# T113-S3 register map
Vendor: Allwinner; Series: T113-S3; File version: 0.1
CPU: other 0, little endian, MPU, no FPU, 0 interrupt priority bits
Registers are 32-bit, read-write, reset 0x0 unless marked. A register's access mark holds for its fields unless they carry their own. Offsets are from the block's base; [hi:lo] are bit positions; lines under a group give offsets from that group; {n}, {i} and the like mark numbered series.

## TCON_LCD0
Base 0x05461000
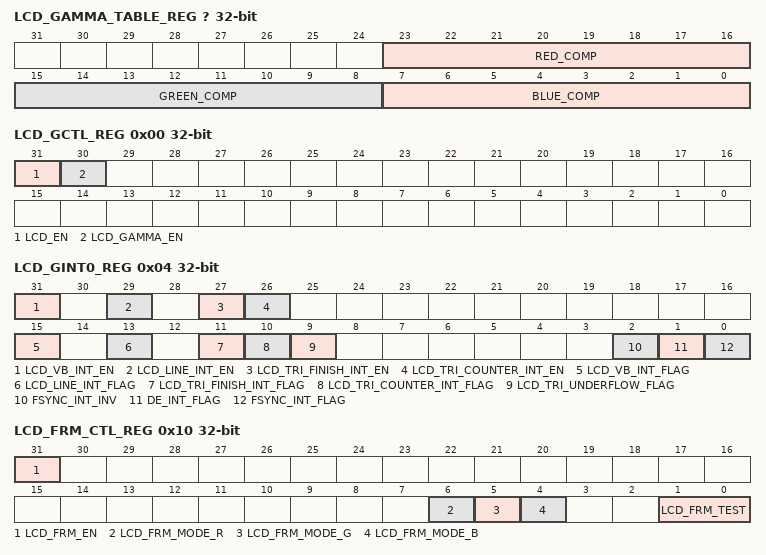
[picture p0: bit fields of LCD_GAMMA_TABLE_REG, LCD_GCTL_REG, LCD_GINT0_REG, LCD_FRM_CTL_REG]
? LCD_GAMMA_TABLE_REG — LCD Gamma Table Register
  [23:16] RED_COMP — Red Component
  [15:8] GREEN_COMP — Green Component
  [7:0] BLUE_COMP — Blue Component
0x00 LCD_GCTL_REG — LCD Global Control Register
  [31] LCD_EN — When it is disabled, the module will be reset to idle state. 0: Disable 1: Enable
    0=Disable; 1=Enable
  [30] LCD_GAMMA_EN — Enable the Gamma correction function. 0: Disable 1: Enable
    0=Disable; 1=Enable
0x04 LCD_GINT0_REG — LCD Global Interrupt Register0
  [31] LCD_VB_INT_EN — Enable the Vb interrupt 0: Disable 1: Enable
    0=Disable; 1=Enable
  [29] LCD_LINE_INT_EN — Enable the line interrupt 0: Disable 1: Enable
    0=Disable; 1=Enable
  [27] LCD_TRI_FINISH_INT_EN — Enable the trigger finish interrupt 0: Disable 1: Enable
    0=Disable; 1=Enable
  [26] LCD_TRI_COUNTER_INT_EN — Enable the trigger counter interrupt 0: Disable 1: Enable
    0=Disable; 1=Enable
  [15] LCD_VB_INT_FLAG write-0-clears — Asserted during vertical no-display period every frame Write 0 to clear it.
  [13] LCD_LINE_INT_FLAG write-0-clears — Trigger when SY0 match the current LCD scan line Write 0 to clear it.
  [11] LCD_TRI_FINISH_INT_FLAG write-0-clears — Trigger when cpu trigger mode finished Write 0 to clear it.
  [10] LCD_TRI_COUNTER_INT_FLAG write-0-clears — Trigger when tri counter reaches this value Write 0 to clear it.
  [9] LCD_TRI_UNDERFLOW_FLAG write-0-clears — Only used in dsi video mode, tri when sync by dsi but not finish Write 0 to clear it.
  [2] FSYNC_INT_INV write-0-clears — Enable the fsync interrupt to set signal inverse polarity. When FSYNC is positive, this bit must be 1. And vice versa.
  [1] DE_INT_FLAG write-0-clears — Asserted at the first valid line in every frame Write 0 to clear it.
  [0] FSYNC_INT_FLAG write-0-clears — Asserted at the fsync signal in every frame Write 0 to clear it.
0x08 LCD_GINT1_REG — LCD Global Interrupt Register1
  [27:16] LCD_LINE_INT_NUM — Scan line for LCD line trigger (including inactive lines). Setting it for the specified line for trigger0.
0x10 LCD_FRM_CTL_REG — LCD FRM Control Register
  [31] LCD_FRM_EN — Enable the dither function 0: Disable 1: Enable
    0=Disable; 1=Enable
  [6] LCD_FRM_MODE_R — The R component output bits in dither function 0: 6-bit frm output 1: 5-bit frm output
    0=6-bit frm output; 1=5-bit frm output
  [5] LCD_FRM_MODE_G — The G component output bits in dither function 0: 6-bit frm output 1: 5-bit frm output
    0=6-bit frm output; 1=5-bit frm output
  [4] LCD_FRM_MODE_B — The B component output bits in dither function 0: 6-bit frm output 1: 5-bit frm output
    0=6-bit frm output; 1=5-bit frm output
  [1:0] LCD_FRM_TEST — Set the test mode of dither function 00: FRM 01: Half 5-/6-bit, half FRM 10: Half 8-bit, half FRM 11: Half 8-bit, half 5-/6-bit
{0x14+4i} xNx[{i}] (i=0..5) — xNx[{i}]
  [24:0] SEED_VALUE — Set the seed used in dither function N=0: Pixel_Seed_R N=1: Pixel_Seed_G N=2: Pixel_Seed_B N=3: Line_Seed_R N=4: Line_Seed_G N=5: Line_Seed_B
{0x2C+4i} LCD_FRM_TAB_REG[{i}] (i=0..3) — LCD FRM Table Register (N=0,1,2,3)
  [31:0] FRM_TABLE_VALUE — Set the data used in dither function Usually set as follows: Table0 = 0x01010000 Table1 = 0x15151111 Table2 = 0x57575555 Table3 = 0x7f7f7777
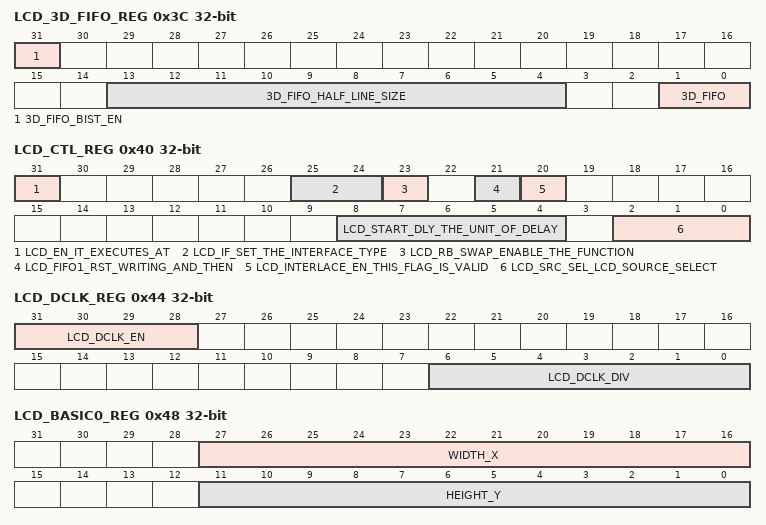
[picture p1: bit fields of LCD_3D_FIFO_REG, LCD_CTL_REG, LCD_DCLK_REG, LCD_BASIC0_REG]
0x3C LCD_3D_FIFO_REG — LCD 3D FIFO Register
  [31] 3D_FIFO_BIST_EN — Enable the 3D fifo bist test function 0: Disable 1: Enable
    0=Disable; 1=Enable
  [13:4] 3D_FIFO_HALF_LINE_SIZE — The number of data in half line=3D_FIFO_HALF_LINE_SIZE+1, only valid when 3D_FIFO_SETTING is set as 2.
  [1:0] 3D_FIFO — Set the work mode of 3D FIFO 00: Bypass 01: Used as normal FIFO 10: Used as 3D interlace FIFO 11: Reserved
0x40 LCD_CTL_REG — LCD Control Register
  [31] LCD_EN_IT_EXECUTES_AT — LCD_EN It executes at the beginning of the first blank line of LCD timing. 0: Disable 1: Enable
    0=Disable; 1=Enable
  [25:24] LCD_IF_SET_THE_INTERFACE_TYPE — LCD_IF Set the interface type of LCD controller. 00: HV(Sync+DE) 01: 8080 I/F 1x: Reserved
    0=HV_openingparen_Sync_plus_DE_closingparen_ (HV(Sync+DE)); 1=8080 I/F
  [23] LCD_RB_SWAP_ENABLE_THE_FUNCTION — LCD_RB_SWAP Enable the function to swap red data and blue data in fifo1. 0: Default 1: Swap RED and BLUE data at FIFO1
    0=Default; 1=Swap RED and BLUE data at FIFO1
  [21] LCD_FIFO1_RST_WRITING_AND_THEN — LCD_FIFO1_RST Writing 1 and then 0 to this bit will reset FIFO 1 Note: 1 holding time must more than 1 DCLK
  [20] LCD_INTERLACE_EN_THIS_FLAG_IS_VALID — LCD_INTERLACE_EN This flag is valid only when LCD_EN == 1 0: Disable 1: Enable
    0=Disable; 1=Enable
  [8:4] LCD_START_DLY_THE_UNIT_OF_DELAY — LCD_START_DLY The unit of delay is T . Note: Valid only when LCD_EN == 1
  [2:0] LCD_SRC_SEL_LCD_SOURCE_SELECT — LCD_SRC_SEL LCD Source Select 000: DE 001: Color Check 010: Grayscale Check 011: Black by White Check 100: Test Data all 0 101: Test Data all 1 110: Reversed 111: Gridding Check
0x44 LCD_DCLK_REG — LCD Data Clock Register
  [31:28] LCD_DCLK_EN — LCD clock enable 0000: dclk_en = 0; dclk1_en = 0; dclk2_en = 0; dclkm2_en = 0; 0001: dclk_en = 1; dclk1_en = 0; dclk2_en = 0; dclkm2_en = 0; 0010: dclk_en = 1; dclk1_en = 0; dclk2_en = 0; dclkm2_en = 1; 0011: dclk_en = 1; dclk1_en = 1; dclk2_en = 0; dclkm2_en = 0; 0101: dclk_en = 1; dclk1_en = 0; dclk2_en = 1; dclkm2_en = 0; 1111: dclk_en = 1; dclk1_en = 1; dclk2_en = 1; dclkm2_en = 1; Others:Reversed
  [6:0] LCD_DCLK_DIV — Tdclk = Tsclk/DCLKDIV Note: 1.If dclk1&dclk2 are used, DCLKDIV >=6 2.If only dclk is used, DCLKDIV >=1
0x48 LCD_BASIC0_REG — LCD Basic Timing Register0
  [27:16] WIDTH_X — Panel width is X+1
  [11:0] HEIGHT_Y — Panel height is Y+1
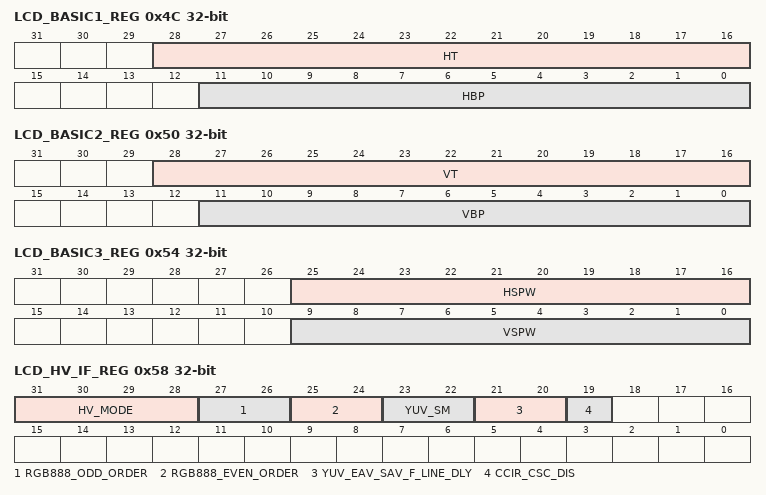
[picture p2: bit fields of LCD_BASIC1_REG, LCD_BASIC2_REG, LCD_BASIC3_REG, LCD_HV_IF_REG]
0x4C LCD_BASIC1_REG — LCD Basic Timing Register1
  [28:16] HT — Thcycle = (HT+1) * Tdclk Computation: 1) parallel: HT = X + BLANK Limitation: 1) parallel: HT >= (HBP +1) + (X+1) +2 2) serial 1: HT >= (HBP +1) + (X+1) *3+2 3) serial 2: HT >= (HBP +1) + (X+1) *3/2+2
  [11:0] HBP — Horizontal back porch (in dclk) Thbp = (HBP +1) * Tdclk
0x50 LCD_BASIC2_REG — LCD Basic Timing Register2
  [28:16] VT — TVT = (VT)/2 * Thsync VT/2 >= (VBP+1 ) + (Y+1) +2
  [11:0] VBP — Tvbp = (VBP +1) * Thsync
0x54 LCD_BASIC3_REG — LCD Basic Timing Register3
  [25:16] HSPW — Thspw = (HSPW+1) * Tdclk HT > (HSPW+1)
  [9:0] VSPW — Tvspw = (VSPW+1) * Thsync VT/2 > (VSPW+1)
0x58 LCD_HV_IF_REG — LCD HV Panel Interface Register
  [31:28] HV_MODE — Set the HV mode of LCD controller 0000: 24-bit/1-cycle parallel mode 1000: 8-bit/3-cycle RGB serial mode (RGB888) 1010: 8-bit/4-cycle Dummy RGB (DRGB) 1011: 8-bit/4-cycle RGB Dummy (RGBD) 1100: 8-bit/2-cycle YUV serial mode (CCIR656)
    0=_24_bit_slash_1_minus_cycle_parallel_mode (24-bit/1-cycle parallel mode); 8=_8_bit_slash_3_minus_cycle_RGB (8-bit/3-cycle RGB serial mode (RGB888)); 10=_8_bit_slash_4_minus_cycle_Dummy (8-bit/4-cycle Dummy RGB (DRGB)); 11=_8_bit_slash_4_minus_cycle_RGB (8-bit/4-cycle RGB Dummy (RGBD)); 12=_8_bit_slash_2_minus_cycle_YUV (8-bit/2-cycle YUV serial mode (CCIR656))
  [27:26] RGB888_ODD_ORDER — Serial RGB888 mode Output sequence at odd lines of the panel (line 1, 3, 5, 7...). 00: R→G→B 01: B→R→G 10: G→B→R 11: R→G→B
  [25:24] RGB888_EVEN_ORDER — Serial RGB888 mode Output sequence at even lines of the panel (line 2, 4, 6, 8...). 00: R→G→B 01: B→R→G 10: G→B→R 11: R→G→B
  [23:22] YUV_SM — Serial YUV mode Output sequence 2-pixel-pair of every scan line. 00: YUYV 01: YVYU 10: UYVY 11: VYUY
    0=YUYV; 1=YVYU; 2=UYVY; 3=VYUY
  [21:20] YUV_EAV_SAV_F_LINE_DLY — Set the delay line mode. 00: F toggle right after active video line 01: delay 2 line (CCIR PAL) 10: delay 3 line (CCIR NTSC) 11: reserved
    0=F toggle right after active video line; 1=delay 2 line (CCIR PAL); 2=delay 3 line (CCIR NTSC)
  [19] CCIR_CSC_DIS — LCD convert source from RGB to YUV. 0: Enable 1: Disable Only valid when HV mode is `1100`.
    0=Enable; 1=Disable Only valid when HV mode is `1100`
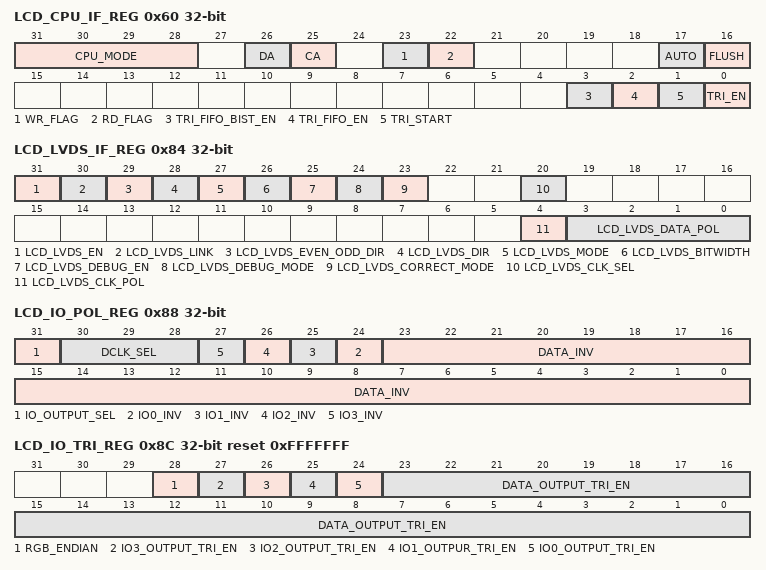
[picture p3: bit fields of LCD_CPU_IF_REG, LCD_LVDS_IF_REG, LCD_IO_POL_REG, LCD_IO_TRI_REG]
0x60 LCD_CPU_IF_REG — LCD CPU Panel Interface Register
  [31:28] CPU_MODE — Set the cpu interface work mode 0000: 18-bit/256K mode 0010: 16-bit mode0 0100: 16-bit mode1 0110: 16-bit mode2 1000: 16-bit mode3 1010: 9-bit mode 1100: 8-bit 256K mode 1110: 8-bit 65K mode xxx1: 24-bit for DSI
    0=_18_bit_slash_256K_mode (18-bit/256K mode); 2=_16_bit_mode0; 4=_16_bit_mode1; 6=_16_bit_mode2; 8=_16_bit_mode3; 10=_9_bit_mode; 12=_8_bit_256K_mode; 14=_8_bit_65K_mode; 1=24-bit for DSI
  [26] DA — Pin A1 value in 8080 mode auto/flash states
  [25] CA — Pin A1 value in 8080 mode WR/RD execute
  [23] WR_FLAG ro — The status of write operation. 0: Write operation is finishing 1: Write operation is pending
    0=finishing (Write operation is finishing); 1=pending (Write operation is pending)
  [22] RD_FLAG ro — The status of read operation. 0: Read operation is finishing 1: Read operation is pending
    0=finishing (Read operation is finishing); 1=pending (Read operation is pending)
  [17] AUTO — Auto transfer mode If it is 1, all the valid data during this frame are written to panel.
  [16] FLUSH — Direct transfer mode If it is enabled, FIFO1 is regardless of the HV timing, the pixels data keep being transferred unless the input FIFO was empty. Data output rate is controlled by DCLK.
  [3] TRI_FIFO_BIST_EN — Entry address is 0xFF8 0: Disable 1: Enable
    0=Disable; 1=Enable
  [2] TRI_FIFO_EN — Enable the trigger FIFO 0: Disable 1: Enable
    0=Disable; 1=Enable
  [1] TRI_START write-1-sets — Software must make sure that write `1` only when this flag is `0`. Writing `1` starts a frame flush and writing `0` has no effect. This flag indicates the frame flush is running.
  [0] TRI_EN — Enable trigger mode 0: Trigger mode disable 1: Trigger mode enable
    0=disable (Trigger mode disable); 1=enable (Trigger mode enable)
0x64 LCD_CPU_WR_REG — LCD CPU Panel Write Data Register
  [23:0] DATA_WR wo — Data write on 8080 bus, launch a write operation on 8080 bus.
0x68 LCD_CPU_RD0_REG — LCD CPU Panel Read Data Register0
  [23:0] DATA_RD0 ro — Data read on 8080 bus, launch a new read operation on 8080 bus.
0x6C LCD_CPU_RD1_REG — LCD CPU Panel Read Data Register1
  [23:0] DATA_RD1 ro — Data read on 8080 bus, without a new read operation on 8080 bus.
0x84 LCD_LVDS_IF_REG — LCD LVDS Configure Register
  [31] LCD_LVDS_EN — Enable LVDS interface 0: Disable 1: Enable
    0=Disable; 1=Enable
  [30] LCD_LVDS_LINK — Select work in single link mode or dual link mode 0: Single link 1: Dual link
    0=Single link; 1=Dual link
  [29] LCD_LVDS_EVEN_ODD_DIR — Set the order of even field and odd field 0: normal 1: reverse
    0=normal; 1=reverse
  [28] LCD_LVDS_DIR — Set the LVDS direction 0: Normal 1: Reverse
    0=Normal; 1=Reverse
  [27] LCD_LVDS_MODE — Set the LVDS data mode 0: NS mode 1: JEIDA mode
    0=NS_mode; 1=JEIDA_mode
  [26] LCD_LVDS_BITWIDTH — Set the bit width of data 0: 24-bit 1: 18-bit
    0=_24_bit; 1=_18_bit
  [25] LCD_LVDS_DEBUG_EN — Enable LVDS debug function 0: Disable 1: Enable
    0=Disable; 1=Enable
  [24] LCD_LVDS_DEBUG_MODE — Set the output signal in debug mode 0: Mode0-Random data 1: Mode1-Output CLK period=7/2 LVDS CLK period
    0=Mode0_minus_Random_data (Mode0-Random data); 1=Mode1_minus_Output (Mode1-Output CLK period=7/2 LVDS CLK period)
  [23] LCD_LVDS_CORRECT_MODE — Set the LVDS correct mode 0: Mode0 1: Mode1
    0=Mode0; 1=Mode1
  [20] LCD_LVDS_CLK_SEL — Select the clock source of LVDS 0: Reserved 1: LCD CLK
    1=LCD (LCD CLK)
  [4] LCD_LVDS_CLK_POL — Set the clock polarity of LVDS 0: Reverse 1: Normal
    0=Reverse; 1=Normal
  [3:0] LCD_LVDS_DATA_POL — Set the data polarity of LVDS 0: Reverse 1: Normal
0x88 LCD_IO_POL_REG — LCD IO Polarity Register
  [31] IO_OUTPUT_SEL — When it is set as `1`, the d[23:0], io0, io1, io3 are sync to dclk. 0: Normal output 1: Register output
    0=Normal output; 1=Register output
  [30:28] DCLK_SEL — Set the phase offset of clock and data in hv mode. 000: Used DCLK0 (normal phase offset) 001: Used DCLK1 (1/3 phase offset) 010: Used DCLK2 (2/3 phase offset) 100: DCLK0/2 phase 0 101: DCLK0/2 phase 90 Others: Reserved
    0=Used_DCLK0__openingparen_normal (Used DCLK0 (normal phase offset)); 1=Used_DCLK1__openingparen_1_slash_3 (Used DCLK1 (1/3 phase offset)); 2=Used_DCLK2__openingparen_2_slash_3 (Used DCLK2 (2/3 phase offset)); 4=DCLK0_slash_2_phase_0 (DCLK0/2 phase 0); 5=DCLK0_slash_2_phase_90 (DCLK0/2 phase 90 Others: Reserved)
  [n+24] IO{n}_INV (n=0..3) — Enable invert function of IO{n} 0: Not invert 1: Invert
    0=Not_invert; 1=Invert
  [23:0] DATA_INV — LCD output port D[23:0] polarity control, with independent bit control. 0: Normal polarity 1: Invert the specify output
0x8C LCD_IO_TRI_REG reset 0xFFFFFFF — LCD IO Control Register
  [28] RGB_ENDIAN — Set the endian of data bits 0: Normal 1: Bits_invert
    0=Normal; 1=Bits_invert
  [27] IO3_OUTPUT_TRI_EN — Enable the output of IO3 1: Disable 0: Enable
    1=Disable; 0=Enable
  [26] IO2_OUTPUT_TRI_EN — Enable the output of IO2 1: Disable 0: Enable
    1=Disable; 0=Enable
  [25] IO1_OUTPUR_TRI_EN — Enable the output of IO1 1: Disable 0: Enable
    1=Disable; 0=Enable
  [24] IO0_OUTPUT_TRI_EN — Enable the output of IO0 1: Disable 0: Enable
    1=Disable; 0=Enable
  [23:0] DATA_OUTPUT_TRI_EN — LCD output port D[23:0] output enable, with independent bit control. 1: Disable 0: Enable
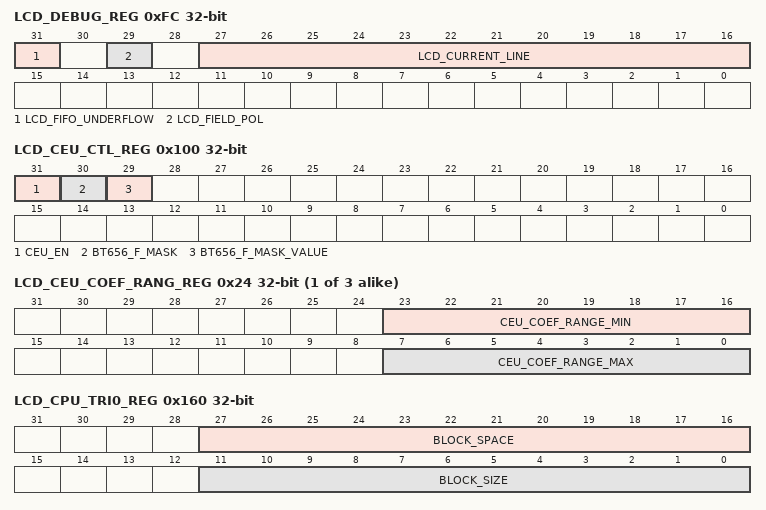
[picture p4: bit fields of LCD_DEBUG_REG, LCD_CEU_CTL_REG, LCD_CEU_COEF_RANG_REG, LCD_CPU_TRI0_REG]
0xFC LCD_DEBUG_REG — LCD Debug Register
  [31] LCD_FIFO_UNDERFLOW ro — The flag shows whether the fifos in underflow status 0: Not underflow 1: Underflow
    0=Not_underflow; 1=Underflow
  [29] LCD_FIELD_POL ro — The flag indicates the current field polarity 0: Second field 1: First field
    0=Second; 1=First
  [27:16] LCD_CURRENT_LINE ro — The current scan line
0x100 LCD_CEU_CTL_REG — LCD CEU Control Register
  [31] CEU_EN — Enable CEU function 0: Bypass 1: Enable
    0=Bypass; 1=Enable
  [30] BT656_F_MASK — BT656 F Mask 0: Disable 1: Enable
    0=Disable; 1=Enable
  [29] BT656_F_MASK_VALUE
{0x110+4i} LCD_CEU_COEF_MUL_REG[{i}] (i=0..10) — LCD CEU Coefficient Register0 (N=0~10)
  [12:0] CEU_COEF_MUL_VALUE — Signed 13-bit value, range of (-16,16). N=0: Rr N=1: Rg N=2: Rb N=4: Gr N=5: Gg N=6: Gb N=8: Br N=9: Bg N=10: Bb
{0x11C+0x10*i} _N[{i}] (i=0..2) group
  0x00 LCD_CEU_COEF_ADD_REG — LCD CEU Coefficient Register1 (N=0,1,2)
    [18:0] CEU_COEF_ADD_VALUE — Signed 19-bit value, range of (-16384, 16384). N=0: Rc N=1: Gc N=2: Bc
  0x24 LCD_CEU_COEF_RANG_REG — LCD CEU Coefficient Register2 (N=0,1,2)
    [23:16] CEU_COEF_RANGE_MIN — Unsigned 8-bit value, range of [0, 255].
    [7:0] CEU_COEF_RANGE_MAX — Unsigned 8-bit value, range of [0, 255].
0x160 LCD_CPU_TRI0_REG — LCD CPU Panel Trigger Register0
  [27:16] BLOCK_SPACE — The spaces between data blocks. It should be set >20*pixel.
  [11:0] BLOCK_SIZE — The size of data block. It is usually set as X.
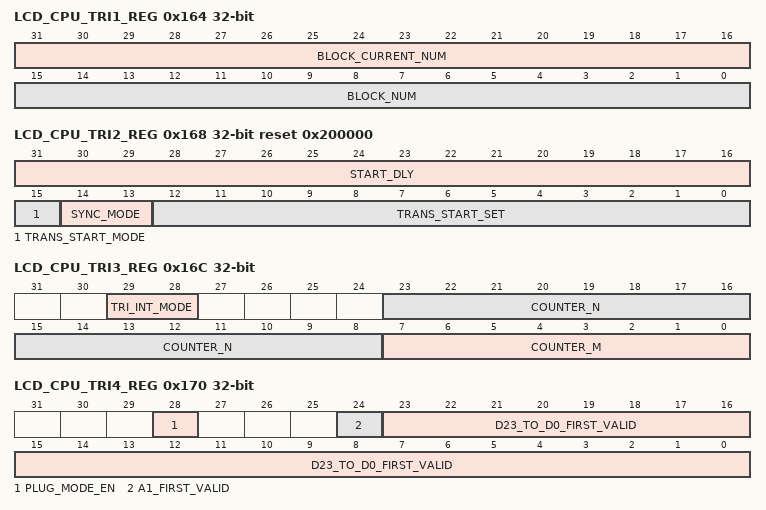
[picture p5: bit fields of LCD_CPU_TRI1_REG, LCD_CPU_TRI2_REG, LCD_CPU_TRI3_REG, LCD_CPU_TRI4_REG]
0x164 LCD_CPU_TRI1_REG — LCD CPU Panel Trigger Register1
  [31:16] BLOCK_CURRENT_NUM ro — Shows the current data block transmitting to panel.
  [15:0] BLOCK_NUM — The number of data blocks. It is usually set as Y.
0x168 LCD_CPU_TRI2_REG reset 0x200000 — LCD CPU Panel Trigger Register2
  [31:16] START_DLY — T = (Start_Delay +1) * be_clk*8.
  [15] TRANS_START_MODE — Select the FIFOs used in CPU mode. 0: ECC_FIFO+TRI_FIFO 1: TRI_FIFO
    0=ECC_FIFO_plus_TRI_FIFO (ECC_FIFO+TRI_FIFO); 1=TRI_FIFO
  [14:13] SYNC_MODE — Set the sync mode in CPU interface. 0x: Auto 10: 0 11: 1
    2=_0; 3=_1
  [12:0] TRANS_START_SET — Usual set as the length of a line.
0x16C LCD_CPU_TRI3_REG — LCD CPU Panel Trigger Register3
  [29:28] TRI_INT_MODE — When set as 01, the Tri_Counter_Int occurs in cycle of (Count_N+1)×(Count_M+1)×4 dclk. When set as 10 or 11, the io0 is map as TE input. 00: Disable 01: Counter mode 10: Te rising mode 11: Te falling mode
  [23:8] COUNTER_N — The value of counter factor
  [7:0] COUNTER_M — The value of counter factor
0x170 LCD_CPU_TRI4_REG — LCD CPU Panel Trigger Register4
  [28] PLUG_MODE_EN — Enable the plug mode used in dsi command mode. 0: Disable 1: Enable
    0=Disable; 1=Enable
  [24] A1_FIRST_VALID — Valid in first Block.
  [23:0] D23_TO_D0_FIRST_VALID — Valid in first Block.
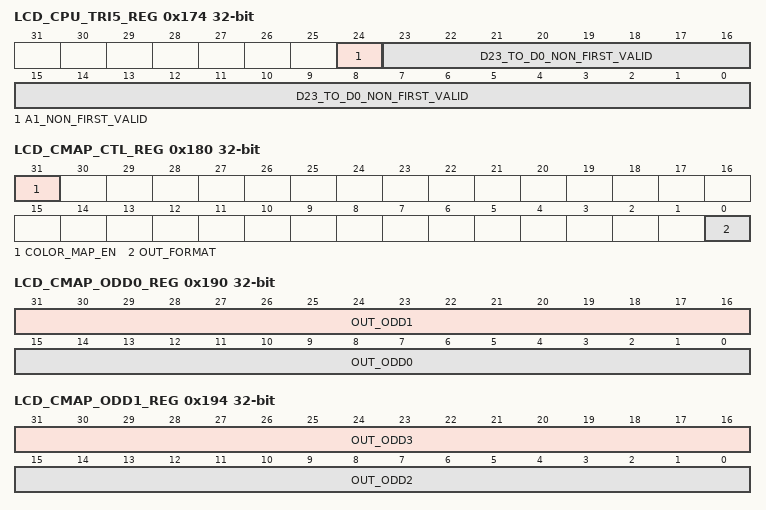
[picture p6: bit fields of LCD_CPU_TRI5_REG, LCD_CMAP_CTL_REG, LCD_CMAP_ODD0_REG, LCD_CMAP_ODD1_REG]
0x174 LCD_CPU_TRI5_REG — LCD CPU Panel Trigger Register5
  [24] A1_NON_FIRST_VALID — Valid in Block except first.
  [23:0] D23_TO_D0_NON_FIRST_VALID — Valid in Block except first.
0x180 LCD_CMAP_CTL_REG — LCD Color Map Control Register
  [31] COLOR_MAP_EN — Enable the color map function. This module only works when X is divided by 4. 0: Bypass 1: Enable
    0=Bypass; 1=Enable
  [0] OUT_FORMAT — Set the pixel output format in color map function. 0: 4 pixel output mode: Out0 -> Out1 -> Out2 -> Out3 1: 2 pixel output mode: Out0 -> Out1
    0=4 pixel output mode: Out0 -> Out1 -> Out2 -> Out3; 1=2 pixel output mode: Out0 -> Out1
0x190 LCD_CMAP_ODD0_REG — LCD Color Map Odd Line Register0
  [31:16] OUT_ODD1 — Indicates the output order of components. bit15-12: Reserved bit11-08: Out_Odd0[23:16] bit07-04: Out_Odd0[15:8] bit03-00: Out_Odd0[7:0] 0000: in_b0 0001: in_g0 0010: in_r0 0011: Reserved 0100: in_b1 0101: in_g1 0110: in_r1 0111:Reserved 1000: in_b2 1001: in_g2 1010: in_r2 1011: Reserved 1100: in_b3 1101: in_g3 1110: in_r3 1111: Reserved
  [15:0] OUT_ODD0 — Indicates the output order of components. bit15-12: Reserved bit11-08: Out_Odd0[23:16] bit07-04: Out_Odd0[15:8] bit03-00: Out_Odd0[7:0] 0000: in_b0 0001: in_g0 0010: in_r0 0011: Reserved 0100: in_b1 0101: in_g1 0110: in_r1 0111:Reserved 1000: in_b2 1001: in_g2 1010: in_r2 1011: Reserved 1100: in_b3 1101: in_g3 1110: in_r3 1111: Reserved
0x194 LCD_CMAP_ODD1_REG — LCD Color Map Odd Line Register1
  [31:16] OUT_ODD3 — Indicates the output order of components. bit15-12: Reserved bit11-08: Out_Odd0[23:16] bit07-04: Out_Odd0[15:8] bit03-00: Out_Odd0[7:0] 0000: in_b0 0001: in_g0 0010: in_r0 0011: Reserved 0100: in_b1 0101: in_g1 0110: in_r1 0111:Reserved 1000: in_b2 1001: in_g2 1010: in_r2 1011: Reserved 1100: in_b3 1101: in_g3 1110: in_r3 1111: Reserved
  [15:0] OUT_ODD2 — Indicates the output order of components. bit15-12: Reserved bit11-08: Out_Odd0[23:16] bit07-04: Out_Odd0[15:8] bit03-00: Out_Odd0[7:0] 0000: in_b0 0001: in_g0 0010: in_r0 0011: Reserved 0100: in_b1 0101: in_g1 0110: in_r1 0111:Reserved 1000: in_b2 1001: in_g2 1010: in_r2 1011: Reserved 1100: in_b3 1101: in_g3 1110: in_r3 1111: Reserved
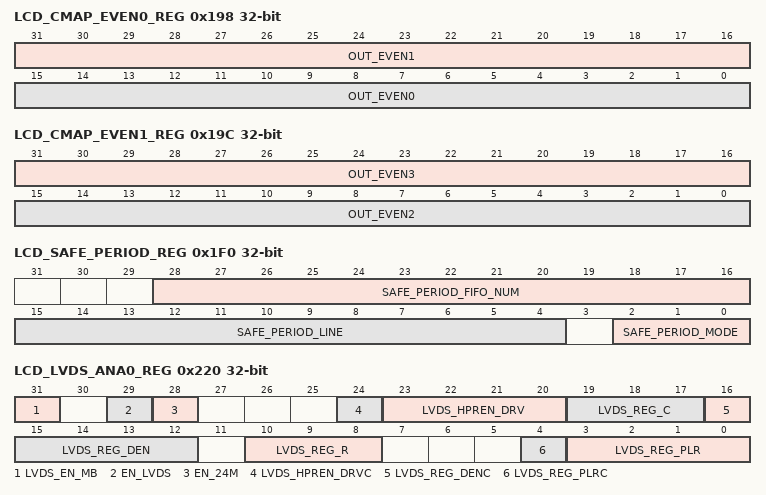
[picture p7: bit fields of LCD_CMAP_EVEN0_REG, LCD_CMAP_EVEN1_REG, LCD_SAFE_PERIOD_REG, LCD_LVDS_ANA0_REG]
0x198 LCD_CMAP_EVEN0_REG — LCD Color Map Even Line Register0
  [31:16] OUT_EVEN1 — Indicates the output order of components. bit15-12: Reserved bit11-08: Out_Odd0[23:16] bit07-04: Out_Odd0[15:8] bit03-00: Out_Odd0[7:0] 0000: in_b0 0001: in_g0 0010: in_r0 0011: Reserved 0100: in_b1 0101: in_g1 0110: in_r1 0111:Reserved 1000: in_b2 1001: in_g2 1010: in_r2 1011: Reserved 1100: in_b3 1101: in_g3 1110: in_r3 1111: Reserved
  [15:0] OUT_EVEN0 — Indicates the output order of components. bit15-12: Reserved bit11-08: Out_Odd0[23:16] bit07-04: Out_Odd0[15:8] bit03-00: Out_Odd0[7:0] 0000: in_b0 0001: in_g0 0010: in_r0 0011: Reserved 0100: in_b1 0101: in_g1 0110: in_r1 0111:Reserved 1000: in_b2 1001: in_g2 1010: in_r2 1011: Reserved 1100: in_b3 1101: in_g3 1110: in_r3 1111: Reserved
0x19C LCD_CMAP_EVEN1_REG — LCD Color Map Even Line Register1
  [31:16] OUT_EVEN3 — Indicates the output order of components. bit15-12: Reserved bit11-08: Out_Odd0[23:16] bit07-04: Out_Odd0[15:8] bit03-00: Out_Odd0[7:0] 0000: in_b0 0001: in_g0 0010: in_r0 0011: Reserved 0100: in_b1 0101: in_g1 0110: in_r1 0111:Reserved 1000: in_b2 1001: in_g2 1010: in_r2 1011: Reserved 1100: in_b3 1101: in_g3 1110: in_r3 1111: Reserved
  [15:0] OUT_EVEN2 — Indicates the output order of components. bit15-12: Reserved bit11-08: Out_Odd0[23:16] bit07-04: Out_Odd0[15:8] bit03-00: Out_Odd0[7:0] 0000: in_b0 0001: in_g0 0010: in_r0 0011: Reserved 0100: in_b1 0101: in_g1 0110: in_r1 0111: Reserved 1000: in_b2 1001: in_g2 1010: in_r2 1011: Reserved 1100: in_b3 1101: in_g3 1110: in_r3 1111: Reserved
0x1F0 LCD_SAFE_PERIOD_REG — LCD Safe Period Register
  [28:16] SAFE_PERIOD_FIFO_NUM — When the data length in line buffer is more than SAFE_PERIOD_FIFO_NUM, the LCD controller will allow dram controller to stop working to change frequency.
  [15:4] SAFE_PERIOD_LINE — Set a fixed line and during the line time, the LCD controller allow dram controller to change frequency. The fixed line should be set in the blanking area.
  [2:0] SAFE_PERIOD_MODE — Select the save mode 000: unsafe 001: safe 010: safe at FIFO_CURR_NUM > SAFE_PERIOD_FIFO_NUM 011: safe at 2 and safe at sync active 100: safe at line
0x220 LCD_LVDS_ANA0_REG
  [31] LVDS_EN_MB — Enable the bias circuit of the LVDS_Ana module. 0: Disable 1: Enable
    0=Disable; 1=Enable
  [29] EN_LVDS — Enable LVDS
  [28] EN_24M — Enable the 24M clock
  [24] LVDS_HPREN_DRVC — Enable clock channel drive 0: Disable 1: Enable
    0=Disable; 1=Enable
  [23:20] LVDS_HPREN_DRV — Enable data channel[3:0] drive 0: Disable 1: Enable
  [19:17] LVDS_REG_C — Adjust current flowing through Rload of Rx to change the differential signals amplitude. 000: 216 mV 001: 252 mV 010: 276 mV 011: 312 mV 100: 336 mV 101: 372 mV 110: 395 mV 111: 432 mV
    0=_216_mV; 1=_252_mV; 2=_276_mV; 3=_312_mV; 4=_336_mV; 5=_372_mV; 6=_395_mV; 7=_432_mV
  [16] LVDS_REG_DENC — Choose data output or PLL test clock output in LVDS_tx.
  [15:12] LVDS_REG_DEN — Choose data output or PLL test clock output in LVDS_tx.
  [10:8] LVDS_REG_R — Adjust current flowing through R of R to change the common signals amplitude. 000: 0.925 V 001: 0.950 V 010: 0.975 V 011: 1.000 V 100: 1.025 V 101: 1.050 V 110: 1.075 V 111: 1.100 V
    0=_0_point_925_V (0.925 V); 1=_0_point_950_V (0.950 V); 2=_0_point_975_V (0.975 V); 3=_1_point_000_V (1.000 V); 4=_1_point_025_V (1.025 V); 5=_1_point_050_V (1.050 V); 6=_1_point_075_V (1.075 V); 7=_1_point_100_V (1.100 V)
  [4] LVDS_REG_PLRC — LVDS clock channel direction. 0: Normal 1: Reverse
    0=Normal; 1=Reverse
  [3:0] LVDS_REG_PLR — LVDS data channel [3:0] direction. 0: Normal 1: Reverse
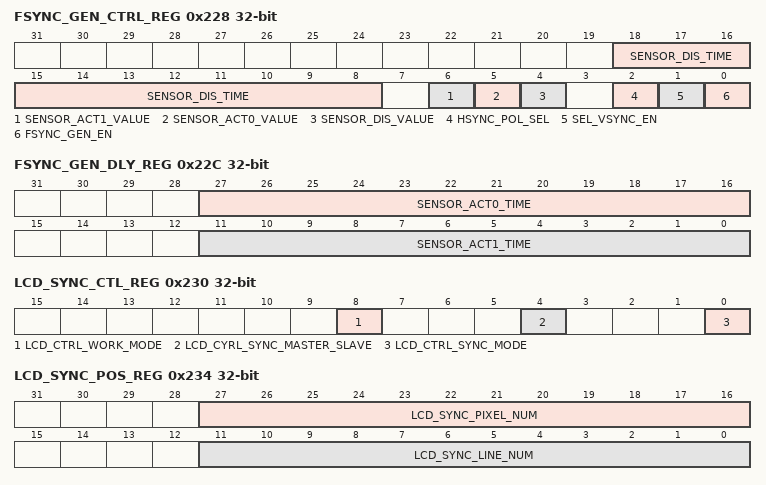
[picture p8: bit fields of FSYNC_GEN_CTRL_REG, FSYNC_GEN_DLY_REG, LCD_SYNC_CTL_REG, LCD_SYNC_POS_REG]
0x228 FSYNC_GEN_CTRL_REG
  [18:8] SENSOR_DIS_TIME — Delay 0-2047 Hsync Period When hsync_pol_sel is 0, the actual delay is sensor_dis_time-1. When hsync_pol_sel is 1, the actual delay is sensor_dis_time.
  [6] SENSOR_ACT1_VALUE — Sensor Active1 Value 0: Fsync active_1 period output 0 1: Fsync active_1 period output 1
    0=Fsync_active_1_period_output_0; 1=Fsync_active_1_period_output_1
  [5] SENSOR_ACT0_VALUE — Sensor Active0 Value 0: Fsync active_0 period output 0 1: Fsync active_0 period output 1
    0=Fsync_active_0_period_output_0; 1=Fsync_active_0_period_output_1
  [4] SENSOR_DIS_VALUE — Sensor Disable Value 0: Fsync disable period output 0 1: Fsync disable period output 1
    0=Fsync_disable_period_output_0; 1=Fsync_disable_period_output_1
  [2] HSYNC_POL_SEL — Hsync Polarity Select 0: Normal 1: Opposite hsync to hysnc counter
    0=Normal; 1=Opposite hsync to hysnc counter
  [1] SEL_VSYNC_EN — Select Vsync Enable 0: Select vsync falling edge to start state machine 1: Select vsync rising edge to start state machine
    0=Select vsync falling edge to start state machine; 1=Select vsync rising edge to start state machine
  [0] FSYNC_GEN_EN — Fsync Generate Enable 0: Disable 1: Enable
    0=Disable; 1=Enable
0x22C FSYNC_GEN_DLY_REG
  [27:16] SENSOR_ACT0_TIME — Delay 0-4095 Pixel clk Period The actual delay is sensor_act0_time+1.
  [11:0] SENSOR_ACT1_TIME — Delay 0-4095 Pixel clk Period The actual delay is sensor_act1_time+1.
0x230 LCD_SYNC_CTL_REG — LCD Sync Control Register
  [8] LCD_CTRL_WORK_MODE — LCD Controller Work mode 0: Single DSI mode 1: Dual DSI mode
    0=Single DSI mode; 1=Dual DSI mode
  [4] LCD_CYRL_SYNC_MASTER_SLAVE — LCD Controller Sync Master Slave 0: Master 1: Slave
    0=Master; 1=Slave
  [0] LCD_CTRL_SYNC_MODE — LCD Controller Sync Mode 0: Sync in the first time 1: Sync every frame
    0=Sync in the first time; 1=Sync every frame
0x234 LCD_SYNC_POS_REG — LCD Sync Position Register
  [27:16] LCD_SYNC_PIXEL_NUM — Set the pixel number of master LCD controller which is used to trigger the slave LCD controller to start working.This value is the number of pixels between the trigger point and the end of the line. Tri pos = Tline*LCD_Sync_Line_Num+Tpixel*(HT-LCD_Sync_Pixel_Num)
  [11:0] LCD_SYNC_LINE_NUM — Set the line number of master LCD controller which is used to trigger the slave LCD controller to start working. Note:It is only set in master LCD controller.It is not necessarily to set in slave LCD controller. Tri pos = Tline*LCD_Sync_Line_Num+Tpixel*(HT-LCD_Sync_Pixel_Num)
0x238 LCD_SLAVE_STOP_POS_REG — LCD Slave Stop Position Register
  [7:0] STOP_VAL — Set the stop position of the slave LCD. This value is the number of pixels between the stop position and the end of the HFP. Stop_pos = HFP - Stop_val. 0<Stop_pos<HFP-2
